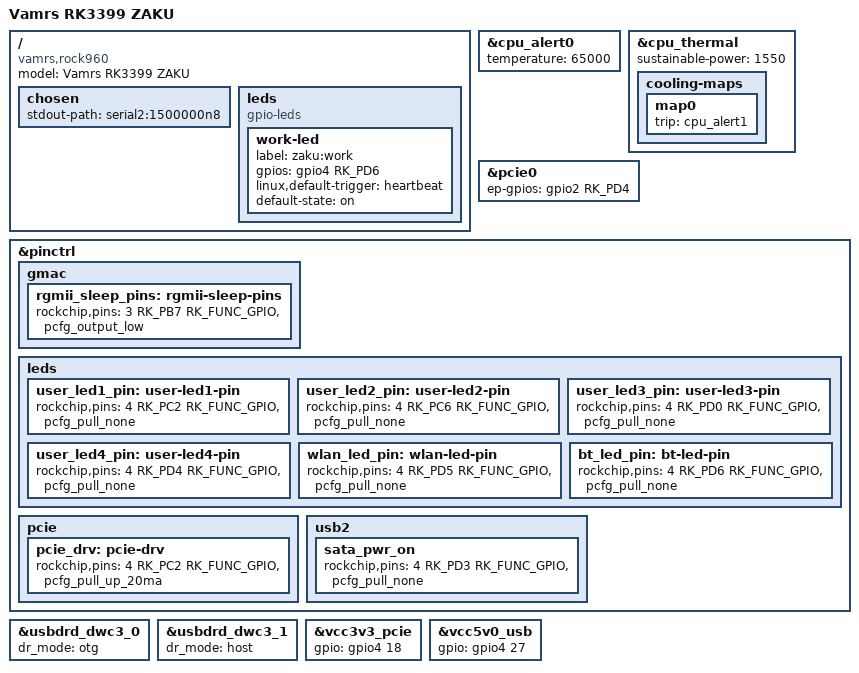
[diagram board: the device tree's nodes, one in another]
// SPDX-License-Identifier: (GPL-2.0+ OR MIT)
/*
 * Copyright (c) 2018 Linaro Ltd.
 */

/dts-v1/;
#include "rk3399-zaku.dtsi"

/ {
	model = "Vamrs RK3399 ZAKU";
	compatible = "vamrs,rock960", "rockchip,rk3399";

	chosen {
		stdout-path = "serial2:1500000n8";
	};
	
	leds {
		compatible = "gpio-leds";
		status = "okay";

		work-led {
			label = "zaku:work";
			gpios = <&gpio4 RK_PD6 GPIO_ACTIVE_HIGH>;
			linux,default-trigger = "heartbeat";
			default-state = "on";
		};
	};


};

&cpu_alert0 {
	temperature = <65000>;
};

&cpu_thermal {
	sustainable-power = <1550>;

	cooling-maps {
		map0 {
			trip = <&cpu_alert1>;
		};
	};
};

&pcie0 {
	ep-gpios = <&gpio2 RK_PD4 GPIO_ACTIVE_HIGH>;
};

&pinctrl {

	gmac {
		rgmii_sleep_pins: rgmii-sleep-pins {
			rockchip,pins =
				<3 RK_PB7 RK_FUNC_GPIO &pcfg_output_low>;
		};
	};

	leds {
		user_led1_pin: user-led1-pin {
			rockchip,pins =
				<4 RK_PC2 RK_FUNC_GPIO &pcfg_pull_none>;
		};

		user_led2_pin: user-led2-pin {
			rockchip,pins =
				<4 RK_PC6 RK_FUNC_GPIO &pcfg_pull_none>;
		};

		user_led3_pin: user-led3-pin {
			rockchip,pins =
				<4 RK_PD0 RK_FUNC_GPIO &pcfg_pull_none>;
		};

		user_led4_pin: user-led4-pin {
			rockchip,pins =
				<4 RK_PD4 RK_FUNC_GPIO &pcfg_pull_none>;
		};

		wlan_led_pin: wlan-led-pin {
			rockchip,pins =
				<4 RK_PD5 RK_FUNC_GPIO &pcfg_pull_none>;
		};

		bt_led_pin: bt-led-pin {
			rockchip,pins =
				<4 RK_PD6 RK_FUNC_GPIO &pcfg_pull_none>;
		};
	};

	pcie {
		pcie_drv: pcie-drv {
			rockchip,pins =
				<4 RK_PC2 RK_FUNC_GPIO &pcfg_pull_up_20ma>;
			};
	};

	usb2 {
		sata_pwr_on: sata_pwr_on {
			rockchip,pins =
				<4 RK_PD3 RK_FUNC_GPIO &pcfg_pull_none>;
		};
	};
};

&usbdrd_dwc3_0 {
	dr_mode = "otg";
};

&usbdrd_dwc3_1 {
	dr_mode = "host";
};
/* Changed Pin */
&vcc3v3_pcie {
	gpio = <&gpio4 18 GPIO_ACTIVE_HIGH>;
};
/* Changed Pin and label */
&vcc5v0_usb {
	gpio = <&gpio4 27 GPIO_ACTIVE_HIGH>;
};

